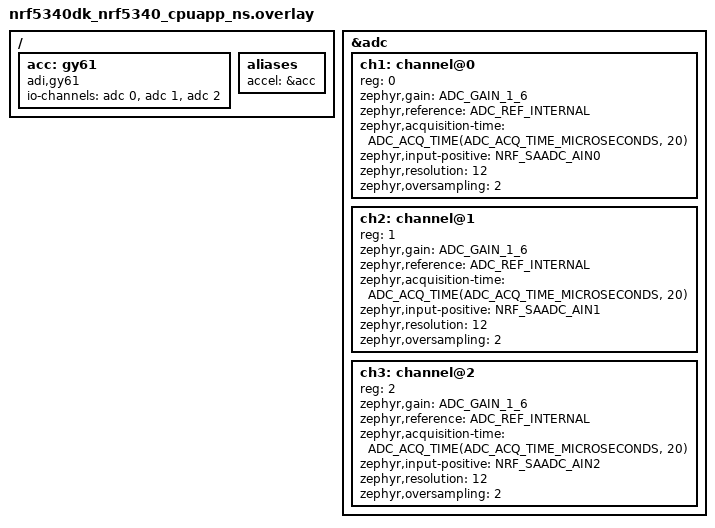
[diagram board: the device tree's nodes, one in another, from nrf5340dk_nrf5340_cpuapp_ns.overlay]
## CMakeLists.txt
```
cmake_minimum_required(VERSION 3.20.0)

find_package(Zephyr REQUIRED HINTS $ENV{ZEPHYR_BASE})

project(accel_sensor)

target_sources(app PRIVATE src/main.c)
target_sources(app PRIVATE src/acc_service.c)
target_sources(app PRIVATE src/acc_sensor.c)
target_sources(app PRIVATE src/acc_nn_calc.c)
target_sources(app PRIVATE src/kmeans.c)
target_sources(app PRIVATE src/conf_matrix.c)
```

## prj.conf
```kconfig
CONFIG_DK_LIBRARY=y
CONFIG_ADC=y

CONFIG_LOG=y
CONFIG_CBPRINTF_FP_SUPPORT=y

CONFIG_BT=y
CONFIG_BT_PERIPHERAL=y
CONFIG_BT_DEVICE_NAME="Accelerometer"

CONFIG_SYSTEM_WORKQUEUE_STACK_SIZE=2048
CONFIG_MAIN_STACK_SIZE=2048
```

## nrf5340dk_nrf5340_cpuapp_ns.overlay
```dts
// help I'm lost

/ {
    acc: gy61 {
        status = "okay";
        compatible = "adi,gy61";
        //label = "gy61";
        io-channels = <&adc 0>, <&adc 1>, <&adc 2>;
    };

    aliases {
        accel = &acc;
    };
};

&adc {
    status = "okay";
    #address-cells = <1>;
    #size-cells = <0>;

    ch1: channel@0 {
        status = "okay";
        reg = <0>;
        zephyr,gain = "ADC_GAIN_1_6";
        zephyr,reference = "ADC_REF_INTERNAL";
        zephyr,acquisition-time = <ADC_ACQ_TIME(ADC_ACQ_TIME_MICROSECONDS, 20)>;
        zephyr,input-positive = <NRF_SAADC_AIN0>;
        zephyr,resolution = <12>;
        zephyr,oversampling = <2>;
    };

    ch2: channel@1 {
        status = "okay";
        reg = <1>;
        zephyr,gain = "ADC_GAIN_1_6";
        zephyr,reference = "ADC_REF_INTERNAL";
        zephyr,acquisition-time = <ADC_ACQ_TIME(ADC_ACQ_TIME_MICROSECONDS, 20)>;
        zephyr,input-positive = <NRF_SAADC_AIN1>;
        zephyr,resolution = <12>;
        zephyr,oversampling = <2>;
    };

    ch3: channel@2 {
        status = "okay";
        reg = <2>;
        zephyr,gain = "ADC_GAIN_1_6";
        zephyr,reference = "ADC_REF_INTERNAL";
        zephyr,acquisition-time = <ADC_ACQ_TIME(ADC_ACQ_TIME_MICROSECONDS, 20)>;
        zephyr,input-positive = <NRF_SAADC_AIN2>;
        zephyr,resolution = <12>;
        zephyr,oversampling = <2>;
    };
};    
```

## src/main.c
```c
#include <stdio.h>
#include <stdlib.h>

#include <zephyr/device.h>
#include <zephyr/devicetree.h>
#include <zephyr/sys/util_macro.h>
#include <zephyr/kernel.h>

#include <dk_buttons_and_leds.h>

#include "acc_service.h"

// How often advertisements are sent out (in units of 0.625 milliseconds, equates to 500 milliseconds)
#define ADVERTISING_INTERVAL 800

#define DEVICE_NAME CONFIG_BT_DEVICE_NAME
#define DEVICE_NAME_LENGTH (sizeof(DEVICE_NAME) - 1)

// Led that blinks when the device is running, and
// the led that is on when the device is connected via BLE
#define STATUS_LED DK_LED1
#define CONNECTION_LED DK_LED2
// Led for indicating the direction for confusion matrix measurements, and
// a led that turns on when the confusion matrix measurement is taking place
#define CM_DIRECTION_LED DK_LED3
#define CM_MEASUREMENT_LED DK_LED4
// Button for sending an indication
#define DATA_BUTTON DK_BTN1_MSK
// The button switching between k-means and neural network for directional calculations,
// the button for choosing the true direction for the confusion matrix, and
// the button for starting the confusion matrix measurement
#define ALGORITHM_BUTTON DK_BTN2_MSK
#define CM_DIRECTION_BUTTON DK_BTN3_MSK
#define CM_START_BUTTON DK_BTN4_MSK

static enum Algorithm chosen_algorithm;
static int true_direction;

// Data for the thread running the measurements
#define STACKSIZE 1024
#define PRIORITY 7

#define BLINK_INTERVAL 500
#define MEASUREMENT_INTERVAL 10000

// 
static const struct bt_data advertisement_data[] = {
    BT_DATA_BYTES(BT_DATA_FLAGS, (BT_LE_AD_GENERAL | BT_LE_AD_NO_BREDR)),
    BT_DATA(BT_DATA_NAME_COMPLETE, DEVICE_NAME, DEVICE_NAME_LENGTH),
    // Our accelerometer service's UUID (but in a weird format)
    BT_DATA_BYTES(BT_DATA_UUID16_ALL, 0xf0, 0x34),
};

// 
static const struct bt_data scan_data[] = {
    BT_DATA_BYTES(BT_DATA_UUID128_ALL, sizeof(ACCELERATION_NOTIFICATION_UUID)),
    BT_DATA_BYTES(BT_DATA_UUID128_ALL, sizeof(ACCELERATION_INDICATION_UUID))
};

// Advertising: can be connected to, advertises twice a second, not directed
static struct bt_le_adv_param *advertisement_parameters = BT_LE_ADV_PARAM(
    (BT_LE_ADV_OPT_CONNECTABLE | BT_LE_ADV_OPT_USE_IDENTITY),
    ADVERTISING_INTERVAL, ADVERTISING_INTERVAL + 1, NULL);

// Bluetooth setup:

// When a bluetooth connection is formed (or tried to)
static void on_connect(struct bt_conn *conn, uint8_t error)
{
    if (error) {
        printk("Something went wrong with connection, error %d.\n", error);
        return;
    }

    printk("Conncted.");
    dk_set_led_on(CONNECTION_LED);
}

// When a bluetooth connection is formed (or tried to)
static void on_disconnect(struct bt_conn *conn, uint8_t reason)
{
    printk("Disconnected, reason %d.\n", reason);
    dk_set_led_off(CONNECTION_LED);
}

// The functions that are called when a connection starts and ends
struct bt_conn_cb connection_callbacks = {
    .connected = on_connect,
    .disconnected = on_disconnect,
};

// ISR for when a button is pressed(?)
static void button_press(uint32_t state, uint32_t change)
{
    // Send an indication with accelerometer data
    if ((state & change) & DATA_BUTTON) {
        read_and_indicate(chosen_algorithm);
    }

    // Change the algorithm for the directional measurements
    if ((state & change) & ALGORITHM_BUTTON) {
        int maxNo = 0;
        #ifdef ACC_NN_CALC_H
        maxNo++;
        #endif
        #ifdef KMEANS_H
        maxNo++;
        #endif
        chosen_algorithm = (chosen_algorithm == maxNo ? 0 : chosen_algorithm + 1);
    }

    // Switch the true direction for the confusion matrix measurement
    if ((state & change) & CM_DIRECTION_BUTTON) {
        // Moves the directional counter ahead one step (0b0000 0001 to 0b0000 0011, for example),
        // Resets to 1 on 
        true_direction = (true_direction == 6 ? 1 : true_direction + 1);
    }

    // Start a confusion matrix measurement
    if ((state & change) & CM_START_BUTTON) {
        confusion_matrix_measurement(chosen_algorithm, true_direction);
    }
}

// Setup of advertising and hardware, then blinking a led
int main(void)
{
    chosen_algorithm = NONE;
    true_direction = 1;

    int16_t blink_counter = 1;
    int error;

    printk("Setting up the device.\n");

    // Led setup
    error = dk_leds_init();
    if (error) {
        printk("Led setup failed, error code %d.\n", error);
        return -1;
    }
    printk("Leds initialized.\n");

    // Button setup
    error = dk_buttons_init(button_press);
    if (error) {
        printk("Button setup failed, error code %d.\n", error);
        return -1;
    }
    printk("Buttons initialized.\n");

    // Bluetooth initialization
    error = bt_enable(NULL);
    if (error) {
        printk("Bluetooth setup failed, error code %d.\n", error);
        return -1;
    }
    printk("Bluetooth initialized.\n");

    // Bluetooth startup
    error = bt_le_adv_start(advertisement_parameters, advertisement_data, ARRAY_SIZE(advertisement_data),
        scan_data, ARRAY_SIZE(scan_data));
    if (error) {
        printk("Bluetooth startup failed, error code %d.\n", error);
        return -1;
    }
    printk("Bluetooth started.\n");

    printk("Device set up succesfully.\n");
    
    while (1) {
        // blink_counter manipulation: the counter should 
        // a. blink the status led on-to-off-to-on every cycle
        // b. be able to blink x times per cycle of 8 to indicate the True Direction(tm)
        // So it's a bit shift thing 
        blink_counter = (blink_counter & 0x8000 ? 1 : blink_counter << 1);
        // Blink the status led to let people know the device is on and running as it should
        dk_set_led(STATUS_LED, ((blink_counter & 0x5555) > 0));
        // The led indicating which direction is set as true for confusion matrix measurements
        // (number of consecutive blinks), as well as the chosen algorithm 
        // (nothing for none, blinks for k-means, "inverted blinks" for neural)
        uint16_t comp = 0x0000;
        switch (chosen_algorithm) {
            case NONE:
                comp = 0xFFFF;
                break;
            #ifdef ACC_NN_CALC_H
            case NEURAL:
                comp = ~(0x5555 >> (2 * (8 - true_direction)));
                break;
            #endif 
            #ifdef KMEANS_H
            case KMEANS:
                comp = 0x5555 >> (2 * (8 - true_direction));
                break;
            #endif
        } 

        dk_set_led(CM_DIRECTION_LED, ((blink_counter & comp) > 0));
        // Take a nap waiting for the next blink interval
        k_sleep(K_MSEC(BLINK_INTERVAL));
    }
}

// A separate thread to take measurements independently of the main loop
void measurement_thread(void)
{
    int error = initialize_accelerometer();
    if (error) {
        printk("Failed to initialize accelerometer, error code %d.\n", error);
        return;
    }
    
    while (1) {
        read_and_notify(chosen_algorithm);
        k_sleep(K_MSEC(MEASUREMENT_INTERVAL));
    }
}

K_THREAD_DEFINE(thread_id, STACKSIZE, measurement_thread, NULL, NULL, NULL, PRIORITY, 0, 0);
```

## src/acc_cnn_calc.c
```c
#include "acc_cnn_calc.h"

int16_t cnn_direction(int16_t x, int16_t y, int16_t z)
{
    double data[] = {(double)x, (double)y, (double)z};
    double outputs[] = {0, 0, 0, 0, 0, 0};
    double weights[3][6] = WEIGHTS;
    double biases[6] = BIASES;
    
    // Dense layer
    for (int i = 0; i < 6; i++) {
        // Perform multiplication
        for (int j = 0; j < 3; j++) {
            outputs[i] += data[j] * weights[j][i];
        }
        // Add biases
        outputs[i] += biases[i];
    }

    // Perform softmax

    int16_t res = 0;
    double largest = 0;
    // Pick out the highest confidence value
    for (int k = 1; k < 7; k++) {
        if (outputs[k-1] > largest) {
            largest = outputs[k-1];
            res = k;
        }
    }

    //printk("Returning from cnn calc: %d", res);

    return res;
}
```

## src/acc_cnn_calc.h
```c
#ifndef ACC_CNN_CALC_H
#define ACC_CNN_CALC_H

#include <stdint.h>
#include "acc_model_weights.h"
#include "conf_matrix.h"

int16_t cnn_direction(int16_t x, int16_t y, int16_t z);

#endif
```

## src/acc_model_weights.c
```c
#include "acc_model_weights.h"

const double weights[3][6] = {{0.9629466, -0.4121402, 0.36320016, 0.4152481, 0.024457145, 0.5744854}, {0.014778692, 0.4039486, 0.27620888, 0.053778205, -0.10028194, 0.36067066}, {0.18876714, 1.1538118, 0.5870183, 0.7683775, 1.2529982, 0.26375347}};
const double biases[6] = {0.34981272, 0.8067101, -0.06119421, 0.9479558, 0.16185836, 0.6727508};
```

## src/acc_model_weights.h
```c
#ifndef WEIGHTS_H_
#define WEIGHTS_H_

extern const double weights[3][6];
extern const double biases[6];

#endif
```

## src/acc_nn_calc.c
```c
#include "acc_nn_calc.h"

int16_t nn_direction(int16_t x, int16_t y, int16_t z)
{
    double data[] = {(double)x, (double)y, (double)z};
    double outputs[] = {0, 0, 0, 0, 0, 0};
    double weights[3][6] = WEIGHTS;
    double biases[6] = BIASES;
    
    // Dense layer
    for (int i = 0; i < 6; i++) {
        // Perform multiplication
        for (int j = 0; j < 3; j++) {
            outputs[i] += data[j] * weights[j][i];
        }
        // Add biases
        outputs[i] += biases[i];
    }

    // Perform softmax

    int16_t res = 0;
    double largest = 0;
    // Pick out the highest confidence value
    for (int k = 1; k < 7; k++) {
        if (outputs[k-1] > largest) {
            largest = outputs[k-1];
            res = k;
        }
    }

    //printk("Returning from nn calc: %d", res);

    return res;
}
```

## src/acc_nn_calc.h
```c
#ifndef ACC_NN_CALC_H
#define ACC_NN_CALC_H

#include <stdint.h>
#include "acc_model_weights.h"
#include "conf_matrix.h"

int16_t nn_direction(int16_t x, int16_t y, int16_t z);

#endif
```

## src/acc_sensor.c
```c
/*
    An accelerometer reader based on the ADC library available on Zephyr. 
    Connects pins defined by the overlay to adc readers, and provides functions 
    for setting up the pins and taking readings.
*/

#include "acc_sensor.h"

#define ACCELEROMETER DT_ALIAS(accel)
#if DT_NODE_HAS_STATUS(ACCELEROMETER, okay)
const struct device *const acc_device =  DEVICE_DT_GET(ACCELEROMETER);
#else
#error "No accelerometer node"
#endif

// Holds the channels for the three input pins
static const struct adc_dt_spec channels[] = {
    ADC_DT_SPEC_GET_BY_IDX(DT_PATH(gy61), 0),
    ADC_DT_SPEC_GET_BY_IDX(DT_PATH(gy61), 1),
    ADC_DT_SPEC_GET_BY_IDX(DT_PATH(gy61), 2)
};

// Declarations for debug/test functions
static int calculate_direction(struct AccelerometerMeasurement *measurement, int algorithm);
static int channel_print(void);
static int sequence_print(struct adc_sequence sequence);

// Basic setup
int initialize_accelerometer(void) 
{
    int err = 0;

    // For each channel (= pin)
    for (int i = 0; i < ARRAY_SIZE(channels); i++) {
		// Check for device readiness
        if (!device_is_ready(channels[i].dev)) {
			printk("Channel %d isn't ready?\n", i);
			return -1;
		}

        // Device tree setup(?)
		err = adc_channel_setup_dt(&channels[i]);
		if (err < 0) {
			printk("Channel %d failed with setup, err %d.\n", i, err);
			return -1;
		}
	}

    // Debug
    channel_print();

    return 0;
}

// Read the accelerometer, return struct holding structs of readings and derived angles
struct AccelerometerMeasurement read_data(int algorithm) 
{
    struct AccelerometerMeasurement data = {
        .acceleration = {
            .x = 0,
            .y = 0,
            .z = 0,
            .direction = 0
        },
        .direction = {
            .x_deg = 0,
            .y_deg = 0,
            .z_deg = 0,
            .magnitude = 0
        }
    };
    
    int16_t temp = 0;
    int32_t large_temp = 0;
    // This thing gets data from the devicetree at adc_sequence_init_dt below and holds things
    // like resolution, oversampling value and such
    struct adc_sequence temp_seq = {
        .buffer = &temp,
        .buffer_size = sizeof(temp)
    };
    int err;

    for (int i = 0; i < ARRAY_SIZE(channels); i++) {        
        // Setup of temp_seq
        err = adc_sequence_init_dt(&channels[i], &temp_seq);
        if (err < 0) {
            printk("Failed to set up channel %d, aborting measurement.Err %d.\n", i+1, err);
            return data;
        }

        // Something something read request
        err = adc_read(channels[i].dev, &temp_seq);
        if (err < 0) {
            printk("Failed to read channel %d, aborting measurement.Err %d.\n", i+1, err);
            return data;
        }

        // Converts whatever magic happened inside the computer to a millivolt value
        // (accelerometer should provide ~1600 for still and ~1900 for the side affected by gravity)
        err = adc_raw_to_millivolts_dt(&channels[i], &large_temp);
        if (err < 0) {
            printk("Error %d with parsing channel %d, aborting measurement.\n", err, i+1);
            return data;
        }

        // Assign data to the bundle of measurements
        switch (i) {
            case 0:
                data.acceleration.x = temp;
                break;
            case 1:
                data.acceleration.y = temp;
                break;
            case 2:
                data.acceleration.z = temp;
                break;
        }
    }

    // 
    int res = calculate_direction(&data, algorithm);
    if (res < 0 || data.acceleration.direction == 0) {
        printk("Failed to calculate direction.\n");
    }

    return data;
}

// Calculates the strength of gravity affecting the device and its direction
static int calculate_direction(struct AccelerometerMeasurement *measurement, int algorithm)
{   
    // Base = voltage when an axis is at 0G, high = voltage when axis is at 1G, one_g = 1G
    // (these are just estimates, the exact value could be gotten through an average of results)
    const uint16_t base = 1910, high = 2275, one_g = high - base;
    const double pi = 3.1415926;

    int16_t x = measurement->acceleration.x, y = measurement->acceleration.y, z = measurement->acceleration.z;
    // How much each axel deviates from the baseline
    int16_t real[] = {x - base, y - base, z - base};
    // Length of the vector (aka strength of acceleration)
    uint16_t mag = sqrt(pow(real[0], 2) + pow(real[1], 2) + pow(real[2], 2));
    // Angle of each axis in degrees
    double deg[3];

    uint16_t final[3];

    for (int i = 0; i < 3; i++) {
        deg[i] = (acos((double)real[i] / mag) * 180 / pi);
        final[i] = (uint16_t)deg[i];
    }

    uint16_t g_val = (uint16_t)((1000*mag)/one_g);

    // Prints
    /*printk("x: %dmV, %d°, y: %dmV, %d°, z: %dmV, %d°, magnitude: %d, acceleration (thousandths of 1G): %d.\n", 
        x, final[0], y, final[1], z, final[2], mag, g_val);*/
    
    // Calculating the acceleration.direction value (one of six)
    uint16_t direction;
    switch (algorithm) {
        #ifdef  ACC_NN_CALC_H
        // Calculated with a convolution neural network because the teacher wanted us to include one
        case NEURAL:
            direction = nn_direction(x, y, z);
            break;
        #endif
        #ifdef  KMEANS_H
        case KMEANS:
            direction = kmeans_direction(x, y, z);
            break;
        #endif
        case NONE:
        default:
            if (final[0] < 45) {direction = 1;}
            // X points down
            else if (135 < final[0]) {direction = 2;}
            // Y points up
            else if (final[1] < 45) {direction = 3;}
            // Y points down
            else if (135 < final[1]) {direction = 4;}
            // Z points up
            else if (final[2] < 45) {direction = 5;}
            // Z points down
            else if (135 < final[2]) {direction = 6;}
            break;
    }
    //printk("Returned from nn calc: %d", direction);

    // Assign all values
    measurement->direction.x_deg = final[0];
    measurement->direction.y_deg = final[1];
    measurement->direction.z_deg = final[2];
    measurement->direction.magnitude = g_val;
    measurement->acceleration.direction = direction;    

    return 0;
}

// Debug
static int channel_print(void) 
{
    printk("channel_print():\n");
    for (int i = 0; i < ARRAY_SIZE(channels); i++) {
        printk("    adc_dt_spec structure, channel %d = \n", i);
        printk("    Device pointer = %p\n", channels[i].dev);
        printk("    Channel Id = %d\n", channels[i].channel_id);
    }

    return 0;
}

// Debug
static int sequence_print(struct adc_sequence sequence) 
{
    printk("sequence_print():\n");
    printk("    Channels: %d\n", sequence.channels);
    printk("    Buffer: %p\n", sequence.buffer);
    printk("    Buffer size: %d\n", sequence.buffer_size);
    printk("    Resolution: %d\n", sequence.resolution);
    printk("    Oversampling: %d\n", sequence.oversampling);

    return 0;
}
```

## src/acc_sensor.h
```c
/*
    An accelerometer reader based on the ADC library available on Zephyr. 
    Connects pins defined by the overlay to adc readers, and provides functions 
    for setting up the pins and taking readings.
*/

#ifndef ACC_SENSOR_H
#define ACC_SENSOR_H

#include <stdint.h>
#include <zephyr/device.h>
#include <zephyr/devicetree.h>
#include <zephyr/kernel.h>
#include <zephyr/drivers/adc.h>
// For direction calculations
#include <math.h>
#include "acc_nn_calc.h"
#include "kmeans.h"

struct AccelerationData {
    uint16_t x;
    uint16_t y;
    uint16_t z;
    uint16_t direction;
};

struct DirectionalData {
    uint16_t x_deg;
    uint16_t y_deg;
    uint16_t z_deg;
    uint16_t magnitude;
};

struct AccelerometerMeasurement {
    struct AccelerationData acceleration;
    struct DirectionalData direction;
};

enum Algorithm {
    NONE,
#ifdef  ACC_NN_CALC_H
    NEURAL,
#endif
#ifdef  KMEANS_H
    KMEANS,
#endif
};

// Accelerometer setup and a means of getting a reading
int initialize_accelerometer(void);
struct AccelerometerMeasurement read_data(int algorithm);

#endif
```

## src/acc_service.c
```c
/*
    Accelerometer service used for advertising the x, y, z and direction values collected from our little device.
    
    Used in conjunction with our sensor, so the sensor is included here and read_and_notify and read_and_indicate
    are built-in.
*/

#include "acc_service.h"

// Whether notification messages should get sent
static bool notify_enabled;
static bool indicate_enabled;
// A collection of parameters concerning indication settings
static struct bt_gatt_indicate_params indication_parameters;

// Holds current reading data
struct AccelerometerMeasurement reading;

// Declarations
static int accelerometer_notification(void);
static int accelerometer_indication(void);
static void indication_callback(struct bt_conn *connection, struct bt_gatt_indicate_params *parameters, uint8_t error);

// Take accelerometer reading and send a notification
int read_and_notify(int algorithm) 
{
    reading = read_data(algorithm);
    if (reading.acceleration.direction == 0) {
        printk("read_and_notify(): error with getting a reading. No notification sent.\n");
        return -1;
    }

    //printk("Values: x = %d, y = %d, z = %d, dir = %d\n", reading.x, reading.y, reading.z, reading.direction);

    int err = accelerometer_notification();
    if (err < 0) {
        //printk("read_and_notify(): error %d sending notification.\n", err);
        return err;
    }
    return 0;
}

// Take accelerometer reading and send an indication
int read_and_indicate(int algorithm) 
{
    reading = read_data(algorithm);
    if (reading.acceleration.direction == 0) {
        printk("read_and_indicate(): error with getting a reading. No indication sent.\n");
        return -1;
    }

    int err = accelerometer_indication();
    if (err < 0) {
        //printk("read_and_indicate(): error %d sending indication.\n", err);
        return err;
    }
    return 0;
}

// Internal workings below

// What gets called when the device you're connected to wants to change notification settings(?)
static void notification_configuration_change(const struct bt_gatt_attr *attributes, uint16_t value)
{
    notify_enabled = (value == BT_GATT_CCC_NOTIFY);

    printk("Notification configuration changed, now %d.\n", notify_enabled);
}

// What gets called when the device you're connected to wants to change indication settings(?)
static void indication_configuration_change(const struct bt_gatt_attr *attributes, uint16_t value)
{
    indicate_enabled = (value == BT_GATT_CCC_INDICATE);

    printk("Indication configuration changed, now %d.\n", indicate_enabled);
}

// Setting up the service and attributes holding our data
BT_GATT_SERVICE_DEFINE(
    accelerometer, 
    // Sets up the service for acceleration measurements
    BT_GATT_PRIMARY_SERVICE(ACCELERATION_SERVICE_UUID),
    //
    BT_GATT_CHARACTERISTIC(ACCELERATION_NOTIFICATION_UUID, BT_GATT_CHRC_NOTIFY, BT_GATT_PERM_READ, NULL, NULL, &reading),
    BT_GATT_CCC(notification_configuration_change, BT_GATT_PERM_READ | BT_GATT_PERM_WRITE),

    BT_GATT_CHARACTERISTIC(ACCELERATION_INDICATION_UUID, BT_GATT_CHRC_INDICATE, BT_GATT_PERM_READ, NULL, NULL, &reading),
    BT_GATT_CCC(indication_configuration_change, BT_GATT_PERM_READ | BT_GATT_PERM_WRITE),
);

// Sends the reading data to a connected device that's subscribed to notifications
static int accelerometer_notification(void)
{
    if (!notify_enabled) {
        return -EACCES;
    }
    // Looks up the acceleration values characteristic (or attribute?) based on its assigned ID
    return bt_gatt_notify(NULL, bt_gatt_find_by_uuid(NULL, 0, ACCELERATION_NOTIFICATION_UUID), &reading, sizeof(reading));
}

// Sends the reading data to a connected device that's subscribed to indications
static int accelerometer_indication(void)
{
    if(!indicate_enabled) {
        return -EACCES;
    }

    indication_parameters.attr = bt_gatt_find_by_uuid(NULL, 0, ACCELERATION_INDICATION_UUID);
	indication_parameters.func = indication_callback;
	indication_parameters.destroy = NULL;
	indication_parameters.data = &reading;
	indication_parameters.len = sizeof(reading);

    return bt_gatt_indicate(NULL, &indication_parameters);
}

// Gets called when an indication has been sent and is answered to
static void indication_callback(struct bt_conn *connection, struct bt_gatt_indicate_params *parameters, uint8_t error) 
{
    printk("Indication callback\n");
}
```

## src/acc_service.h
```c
/*
    Accelerometer service used for advertising the x, y, z and direction values collected from our little device.
    
    Used in conjunction with our sensor, so the sensor is included here and read_and_notify and read_and_indicate
    are built-in.
*/

#ifndef ACC_SERVICE_H
#define ACC_SERVICE_H

#include <stdbool.h>
#include <zephyr/bluetooth/gatt.h>
#include <zephyr/logging/log.h>
#include "acc_sensor.h"

// UUID creation
#define ACCELERATION_SERVICE_UUID_VALUE BT_UUID_128_ENCODE(0xf50234f0, 0x4833, 0x42b8, 0x8d36, 0x983f06b3ee8e)
#define ACCELERATION_NOTIFICATION_UUID_VALUE BT_UUID_128_ENCODE(0xf50234f1, 0x4833, 0x42b8, 0x8d36, 0x983f06b3ee8e)
#define ACCELERATION_INDICATION_UUID_VALUE BT_UUID_128_ENCODE(0xf50234f2, 0x4833, 0x42b8, 0x8d36, 0x983f06b3ee8e)

#define ACCELERATION_SERVICE_UUID BT_UUID_DECLARE_128(ACCELERATION_SERVICE_UUID_VALUE)
#define ACCELERATION_NOTIFICATION_UUID BT_UUID_DECLARE_128(ACCELERATION_NOTIFICATION_UUID_VALUE)
#define ACCELERATION_INDICATION_UUID BT_UUID_DECLARE_128(ACCELERATION_INDICATION_UUID_VALUE)


// The two functions you can use to collect and send data
int read_and_notify(int algorithm);
int read_and_indicate(int algorithm);

#endif
```

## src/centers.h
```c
#ifndef CENTERS_H
#define CENTERS_H

#define CENTERS {{2277.98, 1897.18, 1885.72}, {1513.1, 1890.67, 1902.97}, {1896.29, 2281.54, 1891.97}, {1899.59, 1513.36, 1919.61}, {1900.51, 1919.03, 2283.55}, {1883.84, 1882.11, 1523.13}}

#endif
```

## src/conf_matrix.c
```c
#include "conf_matrix.h"

static int none_matrix[6][6] = {{0,0,0,0,0,0}, {0,0,0,0,0,0}, {0,0,0,0,0,0}, {0,0,0,0,0,0}, {0,0,0,0,0,0}, {0,0,0,0,0,0}};
#ifdef ACC_NN_CALC_H
static int nn_matrix[6][6] = {{0,0,0,0,0,0}, {0,0,0,0,0,0}, {0,0,0,0,0,0}, {0,0,0,0,0,0}, {0,0,0,0,0,0}, {0,0,0,0,0,0}};
#endif
#ifdef KMEANS_H
static int kmeans_matrix[6][6] = {{0,0,0,0,0,0}, {0,0,0,0,0,0}, {0,0,0,0,0,0}, {0,0,0,0,0,0}, {0,0,0,0,0,0}, {0,0,0,0,0,0}};
#endif

void confusion_matrix_measurement(int algorithm, int true_direction) 
{
    int (*matrix)[6][6];
    char printout[30];
    switch (algorithm) {
        #ifdef ACC_NN_CALC_H
        case NEURAL:
            matrix = &nn_matrix;
            strcpy(printout, "neural algorithm chosen");
            break;
        #endif
        #ifdef KMEANS_H
        case KMEANS:
            matrix = &kmeans_matrix;
            strcpy(printout, "k-means algorithm chosen");
            break;
        #endif
        case NONE:
        default:
            matrix = &none_matrix;
            strcpy(printout, "no algorithm chosen");
            break;
    }

    for (int i = 0; i < 100; i++) {
        struct AccelerometerMeasurement measurement = read_data(algorithm);
        // In case of error
        if (measurement.acceleration.direction == 0) {
            continue;
        }
        int result = measurement.acceleration.direction - 1;
        (*matrix)[true_direction - 1][result] += 1;

        k_sleep(K_MSEC(100));
    }

    printk("Confusion matrix results: %s.\n", printout);
    printk("     P R E D I C T E D\n");
    char text[7] = " REAL ";
    for (int j = 0; j < 6; j++) {
        printk("%c [%d] [%d] [%d] [%d] [%d] [%d]\n", text[j], (*matrix)[j][0], (*matrix)[j][1], (*matrix)[j][2], (*matrix)[j][3], (*matrix)[j][4], (*matrix)[j][5]);
    }

    return;
}
```
